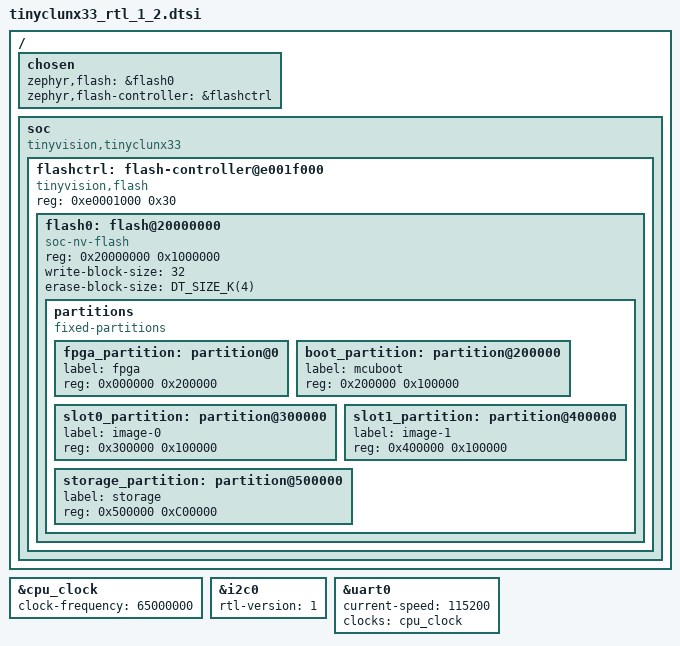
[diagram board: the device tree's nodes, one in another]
/*
 * Copyright (c) tinyVision.ai Inc.
 *
 * SPDX-License-Identifier: Apache-2.0
 */

/*
 * RTL v1.2.x are all the releases that have migrated from LiteX to SpineX.
 *
 * They use 0x200000 as boot address.
 */

#include "tinyclunx33_rtl.dtsi"
#include <mem.h>

/ {
	chosen {
		zephyr,flash = &flash0;
		zephyr,flash-controller = &flashctrl;
	};

	soc {
		compatible = "tinyvision,tinyclunx33";
		ranges;

		flashctrl: flash-controller@e001f000 {
			compatible = "tinyvision,flash";
			reg = <0xe0001000 0x30>;
			#address-cells = <1>;
			#size-cells = <1>;

			flash0: flash@20000000 {
				#address-cells = <1>;
				#size-cells = <0>;
				compatible = "soc-nv-flash";
				reg = <0x20000000 0x1000000>;
				write-block-size = <32>;
				erase-block-size = <DT_SIZE_K(4)>;
			};
		};
	};
};

&flash0 {
	partitions {
		compatible = "fixed-partitions";
		#address-cells = <1>;
		#size-cells = <1>;

		fpga_partition: partition@0 {
			label = "fpga";
			reg = <0x000000 0x200000>;
		};

		boot_partition: partition@200000 {
			label = "mcuboot";
			reg =  <0x200000 0x100000>;
		};

		slot0_partition: partition@300000 {
			label = "image-0";
			reg = <0x300000 0x100000>;
		};

		slot1_partition: partition@400000 {
			label = "image-1";
			reg = <0x400000 0x100000>;
		};

		storage_partition: partition@500000 {
			label = "storage";
			reg = <0x500000 0xC00000>;
		};
	};
};

&cpu_clock {
    clock-frequency = < 65000000 >;
};

&i2c0 {
	rtl-version = <1>;
};

&uart0 {
    current-speed = <115200>;
    clocks = < &cpu_clock >;
};
